AUTOSAR XML (schema 00050)
package /Pkg_ErrorMgrSat_1_0_A/ComponentTypes
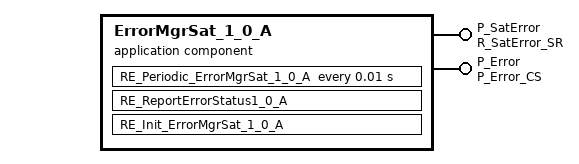
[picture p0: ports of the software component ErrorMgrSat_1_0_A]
  application sw component type ErrorMgrSat_1_0_A
    provide port P_SatError: provided-interface=R_SatError_SR
      provided-com-specs:
        data-element=Data_ErrorMgr_ErrorCommPack_1_0_A, init-value=fields=[RunningCounter:0, Checksum:0, Error:9 x 0, Padding:[0, 0, 0], Data:9 x fields=AdditionalData:16 x 0]
        data-element=Data_ErrorMgr_ErrorCommPack_2_0_A, init-value=fields=[RunningCounter:0, Checksum:0, Error:[0], Padding:[0, 0, 0], Data:[fields=AdditionalData:16 x 0]]
        data-element=Data_ErrorMgr_ErrorCommPack_2_1_A, init-value=fields=[RunningCounter:0, Checksum:0, Error:[0], Padding:[0, 0, 0], Data:[fields=AdditionalData:16 x 0]]
        data-element=Data_ErrorMgr_ErrorCommPack_QNX_A, init-value=fields=[RunningCounter:0, Checksum:0, Error:[0], Padding:[0, 0, 0], Data:[fields=AdditionalData:16 x 0]]
        Data_ErrorMgr_ErrorCommPack_2_0_A
        Data_ErrorMgr_ErrorCommPack_2_1_A
        Data_ErrorMgr_ErrorCommPack_QNX_A
    provide port P_Error: server-com-spec{operation=ReportErrorStatus1_0_A, queue-length=1}, provided-interface=P_Error_CS
    behavior ErrorMgrSat_1_0_A_InternalBehavior: handle-termination-and-restart=NO-SUPPORT
      timing event TMT_RE_Periodic_ErrorMgrSat_1_0_A: start-on-event=RE_Periodic_ErrorMgrSat_1_0_A, period=0.01
      init event InitEvent: start-on-event=RE_Init_ErrorMgrSat_1_0_A
      operation invoked event OIT_RE_ReportErrorStatus1_0_A_P_Error_ReportErrorStatus1_0_A: start-on-event=RE_ReportErrorStatus1_0_A, operation=P_Error.ReportErrorStatus1_0_A
      port-api-options:
        enable-take-address=false, error-handling=NO-TRANSFORMER-ERROR-HANDLING, indirect-api=false, port=P_Error
        enable-take-address=false, error-handling=NO-TRANSFORMER-ERROR-HANDLING, indirect-api=false, port=P_SatError
      runnable RE_Periodic_ErrorMgrSat_1_0_A  # Periodic Runnable of Satellite
        data-send-points:
          4 x access:
            SEND_P_SatError_Data_ErrorMgr_ErrorCommPack_1_0_A: accessed-variable=P_SatError.Data_ErrorMgr_ErrorCommPack_1_0_A
            SEND_P_SatError_Data_ErrorMgr_ErrorCommPack_2_0_A: accessed-variable=P_SatError.Data_ErrorMgr_ErrorCommPack_2_0_A
            SEND_P_SatError_Data_ErrorMgr_ErrorCommPack_2_1_A: accessed-variable=P_SatError.Data_ErrorMgr_ErrorCommPack_2_1_A
            SEND_P_SatError_Data_ErrorMgr_ErrorCommPack_QNX_A: accessed-variable=P_SatError.Data_ErrorMgr_ErrorCommPack_QNX_A
      runnable RE_ReportErrorStatus1_0_A: can-be-invoked-concurrently=true  # Server Runnable for handling the error reporting
      runnable RE_Init_ErrorMgrSat_1_0_A  # Init Runnable
  swc implementation ErrorMgrSat_1_0_A_Implementation: programming-language=C, vendor-id=0, behavior=ErrorMgrSat_1_0_A_InternalBehavior
    code-descriptors:
      code Default: artifact-descriptors=autosar-engineering-object=category=SWSRC
